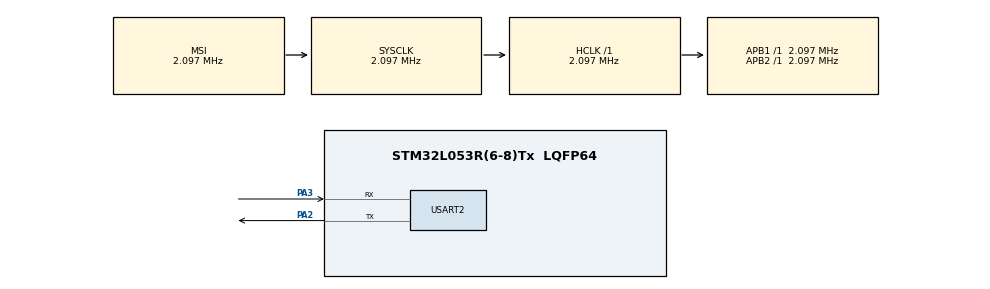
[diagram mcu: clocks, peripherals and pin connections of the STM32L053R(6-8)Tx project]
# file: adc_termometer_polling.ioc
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Dma.Request0=USART2_TX
Dma.USART2_TX.0.Direction=DMA_MEMORY_TO_PERIPH
Dma.USART2_TX.0.Instance=DMA1_Channel4
Dma.USART2_TX.0.MemDataAlignment=DMA_MDATAALIGN_BYTE
Dma.USART2_TX.0.MemInc=DMA_MINC_ENABLE
Dma.USART2_TX.0.Mode=DMA_NORMAL
Dma.USART2_TX.0.PeriphDataAlignment=DMA_PDATAALIGN_BYTE
Dma.USART2_TX.0.PeriphInc=DMA_PINC_DISABLE
Dma.USART2_TX.0.Priority=DMA_PRIORITY_LOW
Mcu.Family=STM32L0
Mcu.Name=STM32L053R(6-8)Tx
Mcu.Package=LQFP64
NVIC.DMA1_Channel4_5_6_7_IRQn=true\:0\:0\:false\:false\:true\:false\:true\:true
NVIC.USART2_IRQn=true\:0\:0\:false\:false\:true\:true\:true\:true
PA2.Mode=Asynchronous
PA2.Signal=USART2_TX
PA3.Mode=Asynchronous
PA3.Signal=USART2_RX
ProjectManager.HeapSize=0x200
ProjectManager.StackSize=0x400
ProjectManager.TargetToolchain=STM32CubeIDE
RCC.AHBFreq_Value=2097000
RCC.APB1Freq_Value=2097000
RCC.APB1TimFreq_Value=2097000
RCC.APB2Freq_Value=2097000
RCC.APB2TimFreq_Value=2097000
RCC.HSE_VALUE=8000000
RCC.HSI16_VALUE=16000000
RCC.HSI48_VALUE=48000000
RCC.HSI_VALUE=16000000
RCC.LSE_VALUE=32768
RCC.MSI_VALUE=2097000
RCC.SYSCLKFreq_VALUE=2097000
RCC.VCOOutputFreq_Value=48000000
USART2.VirtualMode-Asynchronous=VM_ASYNC
VP_ADC_TempSens_Input.Mode=IN-TempSens
board=custom

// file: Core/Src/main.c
/* USER CODE BEGIN Header */
/**
  ******************************************************************************
  * @file           : main.c
  * @brief          : Main program body
  ******************************************************************************
  * @attention
  *
  * Copyright (c) 2023 STMicroelectronics.
  * All rights reserved.
  *
  * This software is licensed under terms that can be found in the LICENSE file
  * in the root directory of this software component.
  * If no LICENSE file comes with this software, it is provided AS-IS.
  *
  ******************************************************************************
  */
/* USER CODE END Header */
#include "main.h"

ADC_HandleTypeDef hadc;

UART_HandleTypeDef huart2;
DMA_HandleTypeDef hdma_usart2_tx;

void SystemClock_Config(void);
static void MX_GPIO_Init(void);
static void MX_DMA_Init(void);
static void MX_ADC_Init(void);
static void MX_USART2_UART_Init(void);

int main(void)
{

  /* MCU Configuration--------------------------------------------------------*/

  /* Reset of all peripherals, Initializes the Flash interface and the Systick. */
  HAL_Init();

  /* Configure the system clock */
  SystemClock_Config();

  /* Initialize all configured peripherals */
  MX_GPIO_Init();
  MX_DMA_Init();
  MX_ADC_Init();
  MX_USART2_UART_Init();
  /* USER CODE BEGIN 2 */
  /* (1) Select HSI16 by writing 00 in CKMODE (reset value) */
  /* (2) Select continuous mode */
  /* (3) Select CHSEL18 for temperature sensor */
  /* (4) Select a sampling mode of 111 i.e. 239.5 ADC clk to be greater
  than 2.2us */
  /* (5) Wake-up the Temperature sensor (only for Temp sensor and
  VRefInt) */
  //ADC1->CFGR2 &= ~ADC_CFGR2_CKMODE; /* (1) */
  ADC1->CFGR1 |= ADC_CFGR1_CONT; /* (2) */
  ADC1->CHSELR = ADC_CHSELR_CHSEL18; /* (3) */
  ADC1->SMPR |= ADC_SMPR_SMP; /* (4) */
  ADC->CCR |= ADC_CCR_TSEN; /* (5) */

  #define TEMP130_CAL_ADDR ((uint16_t*) ((uint32_t) 0x1FF8007E))
  #define TEMP30_CAL_ADDR ((uint16_t*) ((uint32_t) 0x1FF8007A))
  #define VDD_CALIB ((uint16_t) (300))
  #define VDD_APPLI ((uint16_t) (330))

  int32_t ComputeTemperature(uint32_t measure)
  {
    int32_t temperature;
    temperature = ((measure * VDD_APPLI / VDD_CALIB) - (int32_t) *TEMP30_CAL_ADDR );
    temperature = temperature * (int32_t)(130 - 30);
    temperature = temperature / (int32_t)(*TEMP130_CAL_ADDR - *TEMP30_CAL_ADDR);
    //temperature = temperature + 30;
    return(temperature);
  }

  HAL_ADC_Start(&hadc);

  uint32_t mTemperature = 0;

  HAL_ADC_PollForConversion(&hadc, HAL_MAX_DELAY);
  mTemperature = ComputeTemperature(HAL_ADC_GetValue(&hadc));

  HAL_UART_Transmit(&huart2, "\033[0;0H", strlen("\033[0;0H"), HAL_MAX_DELAY);
  HAL_UART_Transmit(&huart2, "\033[2J", strlen("\033[2J"), HAL_MAX_DELAY);

  char value[30];

  sprintf(value, "VALUE: %ld", mTemperature);
  HAL_UART_Transmit(&huart2, value, strlen(value), HAL_MAX_DELAY);
  //  HAL_DMA_Start(&hdma_usart2_tx, (uint32_t)msg, (uint32_t)&huart2.Instance->TDR, strlen(msg));
  // HAL_DMA_Start_IT(&hdma_usart2_tx, &mTemperature, (uint32_t)&huart2.Instance->TDR, strlen(&mTemperature));
  // huart2.Instance->CR3 |= USART_CR3_DMAT;

  /* USER CODE END 2 */

  /* Infinite loop */
  while (1)
  {

  }
}

void SystemClock_Config(void)
{
  RCC_OscInitTypeDef RCC_OscInitStruct = {0};
  RCC_ClkInitTypeDef RCC_ClkInitStruct = {0};
  RCC_PeriphCLKInitTypeDef PeriphClkInit = {0};

  /** Configure the main internal regulator output voltage
  */
  __HAL_PWR_VOLTAGESCALING_CONFIG(PWR_REGULATOR_VOLTAGE_SCALE1);

  /** Initializes the RCC Oscillators according to the specified parameters
  * in the RCC_OscInitTypeDef structure.
  */
  RCC_OscInitStruct.OscillatorType = RCC_OSCILLATORTYPE_MSI;
  RCC_OscInitStruct.MSIState = RCC_MSI_ON;
  RCC_OscInitStruct.MSICalibrationValue = 0;
  RCC_OscInitStruct.MSIClockRange = RCC_MSIRANGE_5;
  RCC_OscInitStruct.PLL.PLLState = RCC_PLL_NONE;
  if (HAL_RCC_OscConfig(&RCC_OscInitStruct) != HAL_OK)
  {
    Error_Handler();
  }

  /** Initializes the CPU, AHB and APB buses clocks
  */
  RCC_ClkInitStruct.ClockType = RCC_CLOCKTYPE_HCLK|RCC_CLOCKTYPE_SYSCLK
                              |RCC_CLOCKTYPE_PCLK1|RCC_CLOCKTYPE_PCLK2;
  RCC_ClkInitStruct.SYSCLKSource = RCC_SYSCLKSOURCE_MSI;
  RCC_ClkInitStruct.AHBCLKDivider = RCC_SYSCLK_DIV1;
  RCC_ClkInitStruct.APB1CLKDivider = RCC_HCLK_DIV1;
  RCC_ClkInitStruct.APB2CLKDivider = RCC_HCLK_DIV1;

  if (HAL_RCC_ClockConfig(&RCC_ClkInitStruct, FLASH_LATENCY_0) != HAL_OK)
  {
    Error_Handler();
  }
  PeriphClkInit.PeriphClockSelection = RCC_PERIPHCLK_USART2;
  PeriphClkInit.Usart2ClockSelection = RCC_USART2CLKSOURCE_PCLK1;
  if (HAL_RCCEx_PeriphCLKConfig(&PeriphClkInit) != HAL_OK)
  {
    Error_Handler();
  }
}

static void MX_ADC_Init(void)
{

  ADC_ChannelConfTypeDef sConfig = {0};

  /** Configure the global features of the ADC (Clock, Resolution, Data Alignment and number of conversion)
  */
  hadc.Instance = ADC1;
  hadc.Init.OversamplingMode = DISABLE;
  hadc.Init.ClockPrescaler = ADC_CLOCK_SYNC_PCLK_DIV1;
  hadc.Init.Resolution = ADC_RESOLUTION_12B;
  hadc.Init.SamplingTime = ADC_SAMPLETIME_1CYCLE_5;
  hadc.Init.ScanConvMode = ADC_SCAN_DIRECTION_FORWARD;
  hadc.Init.DataAlign = ADC_DATAALIGN_RIGHT;
  hadc.Init.ContinuousConvMode = DISABLE;
  hadc.Init.DiscontinuousConvMode = DISABLE;
  hadc.Init.ExternalTrigConvEdge = ADC_EXTERNALTRIGCONVEDGE_NONE;
  hadc.Init.ExternalTrigConv = ADC_SOFTWARE_START;
  hadc.Init.DMAContinuousRequests = DISABLE;
  hadc.Init.EOCSelection = ADC_EOC_SINGLE_CONV;
  hadc.Init.Overrun = ADC_OVR_DATA_PRESERVED;
  hadc.Init.LowPowerAutoWait = DISABLE;
  hadc.Init.LowPowerFrequencyMode = ENABLE;
  hadc.Init.LowPowerAutoPowerOff = DISABLE;
  if (HAL_ADC_Init(&hadc) != HAL_OK)
  {
    Error_Handler();
  }

  /** Configure for the selected ADC regular channel to be converted.
  */
  sConfig.Channel = ADC_CHANNEL_TEMPSENSOR;
  sConfig.Rank = ADC_RANK_CHANNEL_NUMBER;
  if (HAL_ADC_ConfigChannel(&hadc, &sConfig) != HAL_OK)
  {
    Error_Handler();
  }

}

static void MX_USART2_UART_Init(void)
{

  huart2.Instance = USART2;
  huart2.Init.BaudRate = 115200;
  huart2.Init.WordLength = UART_WORDLENGTH_8B;
  huart2.Init.StopBits = UART_STOPBITS_1;
  huart2.Init.Parity = UART_PARITY_NONE;
  huart2.Init.Mode = UART_MODE_TX_RX;
  huart2.Init.HwFlowCtl = UART_HWCONTROL_NONE;
  huart2.Init.OverSampling = UART_OVERSAMPLING_16;
  huart2.Init.OneBitSampling = UART_ONE_BIT_SAMPLE_DISABLE;
  huart2.AdvancedInit.AdvFeatureInit = UART_ADVFEATURE_NO_INIT;
  if (HAL_UART_Init(&huart2) != HAL_OK)
  {
    Error_Handler();
  }

}

static void MX_DMA_Init(void)
{

  /* DMA controller clock enable */
  __HAL_RCC_DMA1_CLK_ENABLE();

  /* DMA interrupt init */
  /* DMA1_Channel4_5_6_7_IRQn interrupt configuration */
  HAL_NVIC_SetPriority(DMA1_Channel4_5_6_7_IRQn, 0, 0);
  HAL_NVIC_EnableIRQ(DMA1_Channel4_5_6_7_IRQn);

}

static void MX_GPIO_Init(void)
{

  /* GPIO Ports Clock Enable */
  __HAL_RCC_GPIOA_CLK_ENABLE();

}

void Error_Handler(void)
{
  __disable_irq();
  while (1)
  {
  }
}
